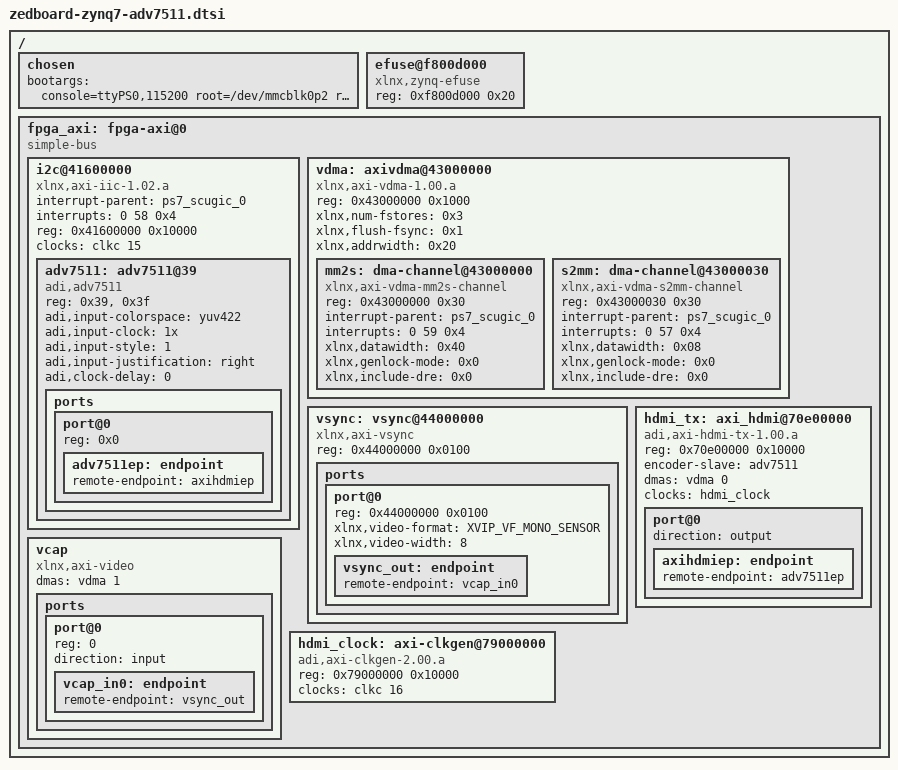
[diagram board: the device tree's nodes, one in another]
/ {
	chosen {
		bootargs = "console=ttyPS0,115200 root=/dev/mmcblk0p2 rw earlyprintk";
	} ;
	efuse@f800d000 {
		compatible = "xlnx,zynq-efuse";
		reg = <0xf800d000 0x20>;
	};
	fpga_axi: fpga-axi@0 {
		compatible = "simple-bus";
		#address-cells = <0x1>;
		#size-cells = <0x1>;
		ranges;

		i2c@41600000 {
			compatible = "xlnx,axi-iic-1.02.a", "xlnx,xps-iic-2.00.a";
			interrupt-parent = <&ps7_scugic_0>;
			interrupts = <0 58 0x4>;
			reg = <0x41600000 0x10000>;
			clocks = <&clkc 15>;

			#size-cells = <0>;
			#address-cells = <1>;

			adv7511: adv7511@39 {
				compatible = "adi,adv7511";
				reg = <0x39>, <0x3f>;
				reg-names = "primary", "edid";

				adi,input-colorspace = "yuv422";
				adi,input-clock = "1x";
				adi,input-style = <1>;
				adi,input-justification = "right";
				adi,clock-delay = <0>;

				#sound-dai-cells = <0>;

				ports {
					#address-cells = <0x1>;
					#size-cells = <0x0>;

					port@0 {
						reg = <0x0>;
						adv7511ep: endpoint {
							remote-endpoint = <&axihdmiep>;
						};
					};
				};
			};
		};

		vdma: axivdma@43000000 {
			compatible = "xlnx,axi-vdma-1.00.a";
			#address-cells = <1>;
			#size-cells = <1>;
			#dma-cells = <1>;
			reg = <0x43000000 0x1000>;
			xlnx,num-fstores = <0x3>;
                        xlnx,flush-fsync = <0x1>;
			xlnx,addrwidth = <0x20>;

			mm2s: dma-channel@43000000 {
				compatible = "xlnx,axi-vdma-mm2s-channel";
				reg = <0x43000000 0x30>;
                                interrupt-parent = <&ps7_scugic_0>;
				interrupts = <0 59 0x4>;
				xlnx,datawidth = <0x40>;
				xlnx,genlock-mode = <0x0>;
				xlnx,include-dre = <0x0>;
			};
			s2mm: dma-channel@43000030 {
				compatible = "xlnx,axi-vdma-s2mm-channel";
				reg = <0x43000030 0x30>;
				interrupt-parent = <&ps7_scugic_0>;
				interrupts = <0 57 0x4>;
				xlnx,datawidth = <0x08>;
				xlnx,genlock-mode = <0x0>;
				xlnx,include-dre = <0x0>;
			};
		};

		vsync: vsync@44000000 {
			compatible = "xlnx,axi-vsync";
			#address-cells = <1>;
			#size-cells = <1>;
			reg = <0x44000000 0x0100>;
			ports {
				#address-cells = <1>;
				#size-cells = <1>;

				port@0 {
					reg = <0x44000000 0x0100>;
					xlnx,video-format = "XVIP_VF_MONO_SENSOR";
					xlnx,video-width = <8>;

					vsync_out: endpoint {
						remote-endpoint = <&vcap_in0>;
					};
				};
			};
		};

		vcap: vcap {
			compatible = "xlnx,axi-video";
			dmas = <&vdma 1>;
			dma-names = "port0";

			ports {
				#address-cells = <1>;
				#size-cells = <0>;

				port@0 {
					reg = <0>;
					direction = "input";
					vcap_in0: endpoint {
						remote-endpoint = <&vsync_out>;
					};
				};
			};
		};

                hdmi_clock: axi-clkgen@79000000 {
			compatible = "adi,axi-clkgen-2.00.a";
			reg = <0x79000000 0x10000>;
			#clock-cells = <0>;
			clocks = <&clkc 16>;
		};

		hdmi_tx: axi_hdmi@70e00000 {
			compatible = "adi,axi-hdmi-tx-1.00.a";
			reg = <0x70e00000 0x10000>;
			encoder-slave = <&adv7511>;
			dmas = <&vdma 0>;
			dma-names = "video";
			clocks = <&hdmi_clock>;

			port@0 {
				direction = "output";
				axihdmiep: endpoint {
					remote-endpoint = <&adv7511ep>;
				};
			};
		};
	};
};
